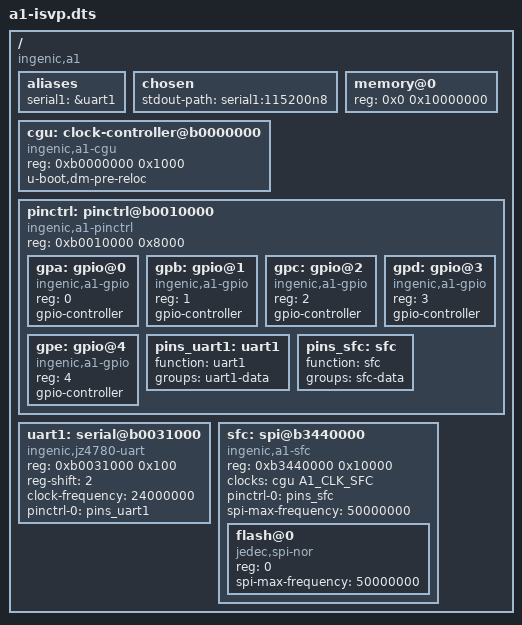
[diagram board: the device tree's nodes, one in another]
// SPDX-License-Identifier: GPL-2.0+
/dts-v1/;

#include <dt-bindings/clock/ingenic,a1-cgu.h>

/ {
	compatible = "ingenic,a1";
	#address-cells = <1>;
	#size-cells = <1>;

	aliases {
		serial1 = &uart1;
	};

	chosen {
		stdout-path = "serial1:115200n8";
	};

	memory@0 {
		device_type = "memory";
		reg = <0x0 0x10000000>;
	};

	cgu: clock-controller@b0000000 {
		compatible = "ingenic,a1-cgu";
		reg = <0xb0000000 0x1000>;
		#clock-cells = <1>;
		u-boot,dm-pre-reloc;
	};

	pinctrl: pinctrl@b0010000 {
		compatible = "ingenic,a1-pinctrl";
		reg = <0xb0010000 0x8000>;
		#address-cells = <1>;
		#size-cells = <0>;

		gpa: gpio@0 {
			compatible = "ingenic,a1-gpio";
			reg = <0>;
			gpio-controller;
			#gpio-cells = <2>;
		};

		gpb: gpio@1 {
			compatible = "ingenic,a1-gpio";
			reg = <1>;
			gpio-controller;
			#gpio-cells = <2>;
		};

		gpc: gpio@2 {
			compatible = "ingenic,a1-gpio";
			reg = <2>;
			gpio-controller;
			#gpio-cells = <2>;
		};

		gpd: gpio@3 {
			compatible = "ingenic,a1-gpio";
			reg = <3>;
			gpio-controller;
			#gpio-cells = <2>;
		};

		gpe: gpio@4 {
			compatible = "ingenic,a1-gpio";
			reg = <4>;
			gpio-controller;
			#gpio-cells = <2>;
		};

		pins_uart1: uart1 {
			function = "uart1";
			groups = "uart1-data";
		};

		pins_sfc: sfc {
			function = "sfc";
			groups = "sfc-data";
		};
	};

	uart1: serial@b0031000 {
		compatible = "ingenic,jz4780-uart", "ns16550a";
		reg = <0xb0031000 0x100>;
		reg-shift = <2>;
		clock-frequency = <24000000>;
		pinctrl-names = "default";
		pinctrl-0 = <&pins_uart1>;
		status = "okay";
	};

	sfc: spi@b3440000 {
		compatible = "ingenic,a1-sfc";
		reg = <0xb3440000 0x10000>;
		#address-cells = <1>;
		#size-cells = <0>;
		clocks = <&cgu A1_CLK_SFC>;
		pinctrl-names = "default";
		pinctrl-0 = <&pins_sfc>;
		spi-max-frequency = <50000000>;
		status = "okay";

		flash@0 {
			compatible = "jedec,spi-nor";
			reg = <0>;
			spi-max-frequency = <50000000>;
		};
	};
};
